# STM32U083 register map
File version: 1.0
CPU: CM0+ r0p1, little endian, MPU, no FPU, 4 interrupt priority bits
Registers are 32-bit, read-write, reset 0x0 unless marked. A register's access mark holds for its fields unless they carry their own. Offsets are from the block's base; [hi:lo] are bit positions; {n}, {i} and the like mark numbered series.

## ADC — ADC address block description
Base 0x40012400
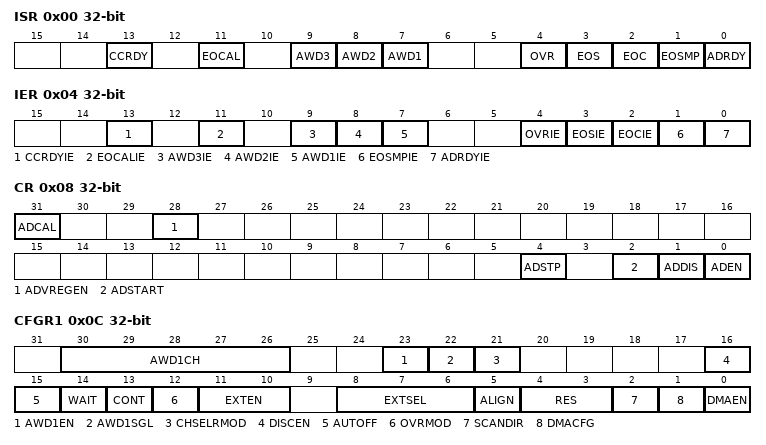
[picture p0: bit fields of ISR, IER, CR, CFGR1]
0x00 ISR — ADC interrupt and status register
  [13] CCRDY — Channel Configuration Ready flag This flag bit is set by hardware when the channel configuration is applied after programming to ADC_CHSELR register or changing CHSELRMOD or SCANDIR. It is cleared by software by programming it to it. Note: When the software configures the channels (by programming ADC_CHSELR or changing CHSELRMOD or SCANDIR), it must wait until the CCRDY flag rises before configuring again or starting conversions, otherwise the new configuration (or the START bit) is ignored. Once the flag is asserted, if the software needs to configure again the channels, it must clear the CCRDY flag before proceeding with a new configuration.
  [11] EOCAL — End Of Calibration flag This bit is set by hardware when calibration is complete. It is cleared by software writing 1 to it.
  [9] AWD3 — Analog watchdog 3 flag This bit is set by hardware when the converted voltage crosses the values programmed in ADC_AWD3TR and ADC_AWD3TR registers. It is cleared by software by programming it to 1.
  [8] AWD2 — Analog watchdog 2 flag This bit is set by hardware when the converted voltage crosses the values programmed in ADC_AWD2TR and ADC_AWD2TR registers. It is cleared by software programming it it.
  [7] AWD1 — Analog watchdog 1 flag This bit is set by hardware when the converted voltage crosses the values programmed in ADC_TR1 and ADC_HR1 registers. It is cleared by software by programming it to 1.
  [4] OVR — ADC overrun This bit is set by hardware when an overrun occurs, meaning that a new conversion has complete while the EOC flag was already set. It is cleared by software writing 1 to it.
  [3] EOS — End of sequence flag This bit is set by hardware at the end of the conversion of a sequence of channels selected by the CHSEL bits. It is cleared by software writing 1 to it.
  [2] EOC — End of conversion flag This bit is set by hardware at the end of each conversion of a channel when a new data result is available in the ADC_DR register. It is cleared by software writing 1 to it or by reading the ADC_DR register.
  [1] EOSMP — End of sampling flag This bit is set by hardware during the conversion, at the end of the sampling phase.It is cleared by software by programming it to 1.
  [0] ADRDY — ADC ready This bit is set by hardware after the ADC has been enabled (ADEN+1) and when the ADC reaches a state where it is ready to accept conversion requests. It is cleared by software writing 1 to it.
0x04 IER — ADC interrupt enable register
  [13] CCRDYIE — Channel Configuration Ready Interrupt enable This bit is set and cleared by software to enable/disable the channel configuration ready interrupt. Note: The software is allowed to write this bit only when ADSTART bit is cleared (this ensures that no conversion is ongoing).
  [11] EOCALIE — End of calibration interrupt enable This bit is set and cleared by software to enable/disable the end of calibration interrupt. Note: The software is allowed to write this bit only when ADSTART bit is cleared (this ensures that no conversion is ongoing).
  [9] AWD3IE — Analog watchdog 3 interrupt enable This bit is set and cleared by software to enable/disable the analog watchdog interrupt. Note: The Software is allowed to write this bit only when ADSTART bit is cleared (this ensures that no conversion is ongoing).
  [8] AWD2IE — Analog watchdog 2 interrupt enable This bit is set and cleared by software to enable/disable the analog watchdog interrupt. Note: The Software is allowed to write this bit only when ADSTART bit is cleared (this ensures that no conversion is ongoing).
  [7] AWD1IE — Analog watchdog 1 interrupt enable This bit is set and cleared by software to enable/disable the analog watchdog interrupt. Note: The Software is allowed to write this bit only when ADSTART bit is cleared (this ensures that no conversion is ongoing).
  [4] OVRIE — Overrun interrupt enable This bit is set and cleared by software to enable/disable the overrun interrupt. Note: The software is allowed to write this bit only when ADSTART bit is cleared (this ensures that no conversion is ongoing).
  [3] EOSIE — End of conversion sequence interrupt enable This bit is set and cleared by software to enable/disable the end of sequence of conversions interrupt. Note: The software is allowed to write this bit only when ADSTART bit is cleared (this ensures that no conversion is ongoing).
  [2] EOCIE — End of conversion interrupt enable This bit is set and cleared by software to enable/disable the end of conversion interrupt. Note: The software is allowed to write this bit only when ADSTART bit is cleared (this ensures that no conversion is ongoing).
  [1] EOSMPIE — End of sampling flag interrupt enable This bit is set and cleared by software to enable/disable the end of the sampling phase interrupt. Note: The software is allowed to write this bit only when ADSTART bit is cleared (this ensures that no conversion is ongoing).
  [0] ADRDYIE — ADC ready interrupt enable This bit is set and cleared by software to enable/disable the ADC Ready interrupt. Note: The software is allowed to write this bit only when ADSTART bit is cleared (this ensures that no conversion is ongoing).
0x08 CR — ADC control register
  [31] ADCAL — ADC calibration This bit is set by software to start the calibration of the ADC.
  [28] ADVREGEN — ADC Voltage Regulator Enable
  [4] ADSTP — ADC stop conversion command
  [2] ADSTART — ADC start conversion command
  [1] ADDIS — ADC disable command
  [0] ADEN — ADC enable command This bit is set by software to enable the ADC. The ADC is effectively ready to operate once the ADRDY flag has been set. It is cleared by hardware when the ADC is disabled, after the execution of the ADDIS command.
0x0C CFGR1 — ADC configuration register 1
  [30:26] AWD1CH — Analog watchdog channel selection These bits are set and cleared by software. They select the input channel to be guarded by the analog watchdog. ..... Others: Reserved Note: The channel selected by the AWDCH[4:0] bits must be also set into the CHSELR register.
  [23] AWD1EN — Analog watchdog enable This bit is set and cleared by software.
  [22] AWD1SGL — Enable the watchdog on a single channel or on all channels This bit is set and cleared by software to enable the analog watchdog on the channel identified by the AWDCH[4:0] bits or on all the channels
  [21] CHSELRMOD — Mode selection of the ADC_CHSELR register This bit is set and cleared by software to control the ADC_CHSELR feature: Note: If CCRDY is not yet asserted after channel configuration (writing ADC_CHSELR register or changing CHSELRMOD or SCANDIR), the value written to this bit is ignored.
  [16] DISCEN — Discontinuous mode This bit is set and cleared by software to enable/disable discontinuous mode. Note: It is not possible to have both discontinuous mode and continuous mode enabled: it is forbidden to set both bits DISCEN1=11 and CONT1=11.
  [15] AUTOFF — Auto-off mode This bit is set and cleared by software to enable/disable auto-off mode.<sup>.</sup>
  [14] WAIT — Wait conversion mode This bit is set and cleared by software to enable/disable wait conversion mode.<sup>.</sup>
  [13] CONT — Single / continuous conversion mode This bit is set and cleared by software. If it is set, conversion takes place continuously until it is cleared. Note: It is not possible to have both discontinuous mode and continuous mode enabled: it is forbidden to set both bits DISCEN1=11 and CONT1=11.
  [12] OVRMOD — Overrun management mode This bit is set and cleared by software and configure the way data overruns are managed.
  [11:10] EXTEN — External trigger enable and polarity selection These bits are set and cleared by software to select the external trigger polarity and enable the trigger.
  [8:6] EXTSEL — External trigger selection These bits select the external event used to trigger the start of conversion (refer to Table160: External triggers for details):
  [5] ALIGN — Data alignment This bit is set and cleared by software to select right or left alignment. Refer to Figure141: Data alignment and resolution (oversampling disabled: OVSE = 0) on page1332
  [4:3] RES — Data resolution These bits are written by software to select the resolution of the conversion.
  [2] SCANDIR — Scan sequence direction This bit is set and cleared by software to select the direction in which the channels is scanned in the sequence. It is effective only if CHSELMOD bit is cleared. Note: If CCRDY is not yet asserted after channel configuration (writing ADC_CHSELR register or changing CHSELRMOD or SCANDIR), the value written to this bit is ignored.
  [1] DMACFG — Direct memory access configuration This bit is set and cleared by software to select between two DMA modes of operation and is effective only when DMAEN1=11. For more details, refer to Section113.6.5: Managing converted data using the DMA on page1333.
  [0] DMAEN — Direct memory access enable This bit is set and cleared by software to enable the generation of DMA requests. This allows the DMA controller to be used to manage automatically the converted data. For more details, refer to Section113.6.5: Managing converted data using the DMA on page1333.
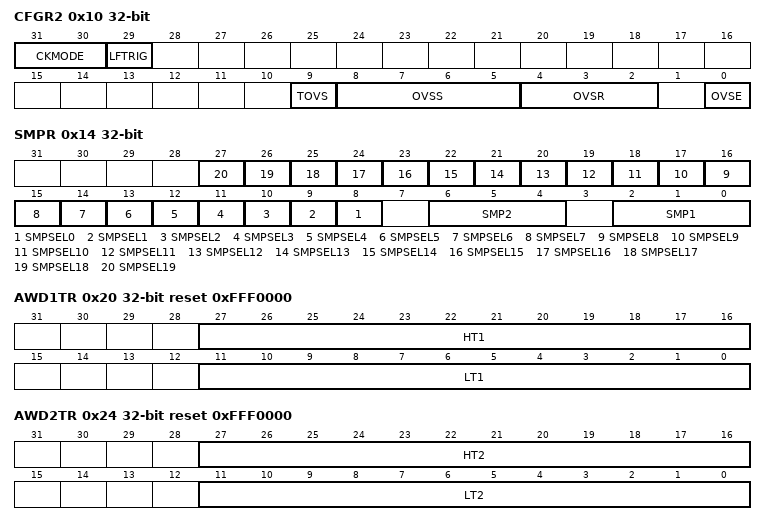
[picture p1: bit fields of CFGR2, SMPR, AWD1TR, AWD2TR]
0x10 CFGR2 — ADC configuration register 2
  [31:30] CKMODE — ADC clock mode These bits are set and cleared by software to define how the analog ADC is clocked: In all synchronous clock modes, there is no jitter in the delay from a timer trigger to the start of a conversion. Note: The software is allowed to write these bits only when the ADC is disabled (ADCAL1=10, ADSTART1=10, ADSTP1=10, ADDIS1=10 and ADEN1=10).
  [29] LFTRIG — Low frequency trigger mode enable This bit is set and cleared by software. Note: The software is allowed to write this bit only when ADEN bit is cleared.
  [9] TOVS — Triggered Oversampling This bit is set and cleared by software. Note: The software is allowed to write this bit only when ADEN bit is cleared.
  [8:5] OVSS — Oversampling shift This bit is set and cleared by software. Others: Reserved Note: The software is allowed to write this bit only when ADEN bit is cleared.
  [4:2] OVSR — Oversampling ratio This bit filed defines the number of oversampling ratio. Note: The software is allowed to write this bit only when ADEN bit is cleared.
  [0] OVSE — Oversampler Enable This bit is set and cleared by software. Note: The software is allowed to write this bit only when ADEN bit is cleared.
0x14 SMPR — ADC sampling time register
  [n+8] SMPSEL{n} (n=0..19) — Channel-x sampling time selection (x1=119 to 0) These bits are written by software to define which sampling time is used. Note: The software is allowed to write this bit only when ADSTART1=10 (which ensures that no conversion is ongoing).
  [6:4] SMP2 — Sampling time selection 2 These bits are written by software to select the sampling time that applies to all channels. Note: The software is allowed to write this bit only when ADSTART=0 (which ensures that no conversion is ongoing).
  [2:0] SMP1 — Sampling time selection 1 These bits are written by software to select the sampling time that applies to all channels. Note: The software is allowed to write this bit only when ADSTART=0 (which ensures that no conversion is ongoing).
0x20 AWD1TR reset 0xFFF0000 — ADC watchdog threshold register
  [27:16] HT1 — Analog watchdog 1 higher threshold These bits are written by software to define the higher threshold for the analog watchdog. Refer to Section113.8: Analog window watchdogs on page1337.
  [11:0] LT1 — Analog watchdog 1 lower threshold These bits are written by software to define the lower threshold for the analog watchdog. Refer to Section113.8: Analog window watchdogs on page1337.
0x24 AWD2TR reset 0xFFF0000 — ADC watchdog threshold register
  [27:16] HT2 — Analog watchdog 2 higher threshold These bits are written by software to define the higher threshold for the analog watchdog. Refer to Section113.8: Analog window watchdogs on page1337.
  [11:0] LT2 — Analog watchdog 2 lower threshold These bits are written by software to define the lower threshold for the analog watchdog. Refer to Section113.8: Analog window watchdogs on page1337.
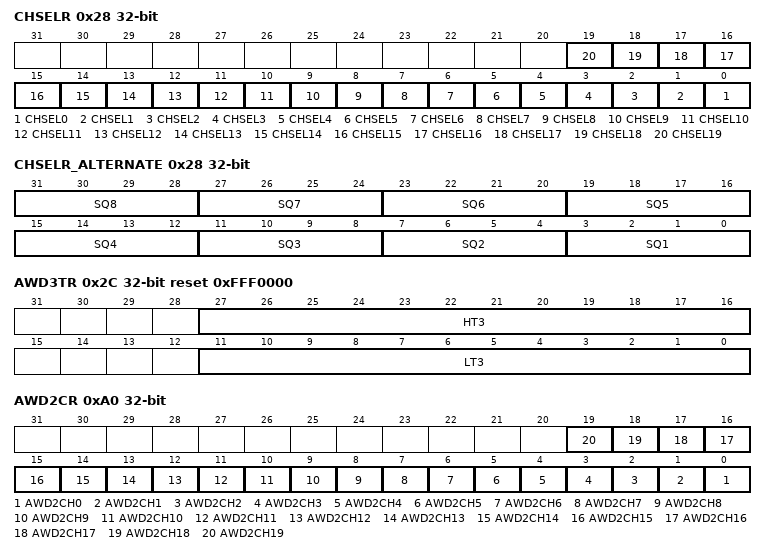
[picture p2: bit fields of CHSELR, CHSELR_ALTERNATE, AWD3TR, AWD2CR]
0x28 CHSELR — ADC channel selection register
  [n] CHSEL{n} (n=0..19) — Channel-x selection These bits are written by software and define which channels are part of the sequence of channels to be converted. Note: The software is allowed to write this bit only when ADSTART1=10 (which ensures that no conversion is ongoing). Note: If CCRDY is not yet asserted after channel configuration (writing ADC_CHSELR register or changing CHSELRMOD or SCANDIR), the value written to this bit is ignored.
0x28 CHSELR_ALTERNATE (alternate view of CHSELR) — ADC channel selection register
  [31:28] SQ8 — 8th conversion of the sequence These bits are programmed by software with the channel number (0...14) assigned to the 8th conversion of the sequence. 0b1111 indicates the end of the sequence. When 0b1111 (end of sequence) is programmed to the lower sequence channels, these bits are ignored. ... Note: The software is allowed to write this bit only when ADSTART1=10 (which ensures that no conversion is ongoing).
  [4n-1:4n-4] SQ{n} (n=4..7) — {n}th conversion of the sequence These bits are programmed by software with the channel number (0...14) assigned to the 8th conversion of the sequence. 0b1111 indicates end of the sequence. When 0b1111 (end of sequence) is programmed to the lower sequence channels, these bits are ignored. Refer to SQ8[3:0] for a definition of channel selection. Note: The software is allowed to write this bit only when ADSTART1=10 (which ensures that no conversion is ongoing).
  [11:8] SQ3 — 3rd conversion of the sequence These bits are programmed by software with the channel number (0...14) assigned to the 8th conversion of the sequence. 0b1111 indicates end of the sequence. When 0b1111 (end of sequence) is programmed to the lower sequence channels, these bits are ignored. Refer to SQ8[3:0] for a definition of channel selection. Note: The software is allowed to write this bit only when ADSTART1=10 (which ensures that no conversion is ongoing).
  [7:4] SQ2 — 2nd conversion of the sequence These bits are programmed by software with the channel number (0...14) assigned to the 8th conversion of the sequence. 0b1111 indicates end of the sequence. When 0b1111 (end of sequence) is programmed to the lower sequence channels, these bits are ignored. Refer to SQ8[3:0] for a definition of channel selection. Note: The software is allowed to write this bit only when ADSTART1=10 (which ensures that no conversion is ongoing).
  [3:0] SQ1 — 1st conversion of the sequence These bits are programmed by software with the channel number (0...14) assigned to the 8th conversion of the sequence. 0b1111 indicates end of the sequence. When 0b1111 (end of sequence) is programmed to the lower sequence channels, these bits are ignored. Refer to SQ8[3:0] for a definition of channel selection. Note: The software is allowed to write this bit only when ADSTART1=10 (which ensures that no conversion is ongoing).
0x2C AWD3TR reset 0xFFF0000 — ADC watchdog threshold register
  [27:16] HT3 — Analog watchdog 3 higher threshold These bits are written by software to define the higher threshold for the analog watchdog. Refer to Section113.8: Analog window watchdogs on page1337.
  [11:0] LT3 — Analog watchdog 3lower threshold These bits are written by software to define the lower threshold for the analog watchdog. Refer to Section113.8: Analog window watchdogs on page1337.
0x40 DR ro — ADC data register
  [15:0] DATA — Converted data These bits are read-only. They contain the conversion result from the last converted channel. The data are left- or right-aligned as shown in Figure141: Data alignment and resolution (oversampling disabled: OVSE = 0) on page1332. Just after a calibration is complete, DATA[6:0] contains the calibration factor.
0xA0 AWD2CR — ADC analog watchdog 2 configuration register
  [n] AWD2CH{n} (n=0..19) — Analog watchdog channel selection These bits are set and cleared by software. They enable and select the input channels to be guarded by analog watchdog 2 (AWD2). Note: The channels selected through ADC_AWD2CR must be also configured into the ADC_CHSELR registers. The software is allowed to write this bit only when ADSTART1=10 (which ensures that no conversion is ongoing).
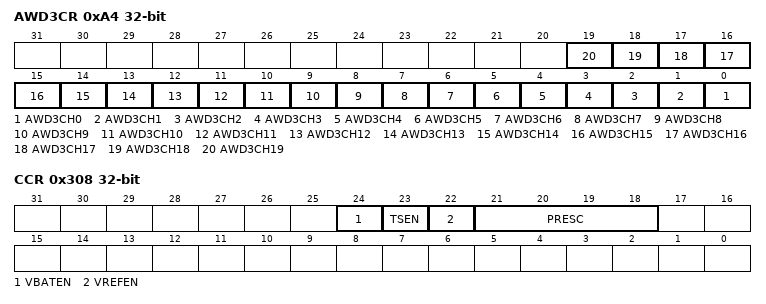
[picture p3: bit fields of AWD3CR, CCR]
0xA4 AWD3CR — ADC Analog Watchdog 3 Configuration register
  [n] AWD3CH{n} (n=0..19) — Analog watchdog channel selection These bits are set and cleared by software. They enable and select the input channels to be guarded by analog watchdog 3 (AWD3). Note: The channels selected through ADC_AWD3CR must be also configured into the ADC_CHSELR registers. The software is allowed to write this bit only when ADSTART=0 (which ensures that no conversion is ongoing).
0xB4 CALFACT — ADC calibration factor
  [6:0] CALFACT — Calibration factor These bits are written by hardware or by software. Once a calibration is complete,1they are updated by hardware with the calibration factors. Software can write these bits with a new calibration factor. If the new calibration factor is different from the current one stored into the analog ADC, it is then applied once a new conversion is launched. Just after a calibration is complete, DATA[6:0] contains the calibration factor. Note: Software can write these bits only when ADEN=1 (ADC is enabled and no calibration is ongoing and no conversion is ongoing).
0x308 CCR — ADC common configuration register
  [24] VBATEN — V<sub>BAT</sub> enable This bit is set and cleared by software to enable/disable the V<sub>BAT</sub> channel. Note: The software is allowed to write this bit only when ADSTART1=10 (which ensures that no conversion is ongoing)
  [23] TSEN — Temperature sensor enable This bit is set and cleared by software to enable/disable the temperature sensor. Note: Software is allowed to write this bit only when ADSTART1=10 (which ensures that no conversion is ongoing).
  [22] VREFEN — V<sub>REFINT</sub> enable This bit is set and cleared by software to enable/disable the V<sub>REFINT</sub>. Note: Software is allowed to write this bit only when ADSTART1=10 (which ensures that no conversion is ongoing).
  [21:18] PRESC — ADC prescaler Set and cleared by software to select the frequency of the clock to the ADC. Other: Reserved Note: Software is allowed to write these bits only when the ADC is disabled (ADCAL1=10, ADSTART1=10, ADSTP1=10, ADDIS1=10 and ADEN1=10).
